# MKW36Z4 register map
Vendor: NXP Semiconductors; Series: Kinetis_W; File version: 1.6
CPU: CM0PLUS r0p0, little endian, no MPU, no FPU, VTOR, 2 interrupt priority bits
Registers are 16-bit, read-write, no defined reset value unless marked. A register's access mark holds for its fields unless they carry their own. Offsets are from the block's base; [hi:lo] are bit positions; {n}, {i} and the like mark numbered series; 'fields as' and 'values as' point back to an identical list.

## PORTC — PORT
Base 0x4004B000
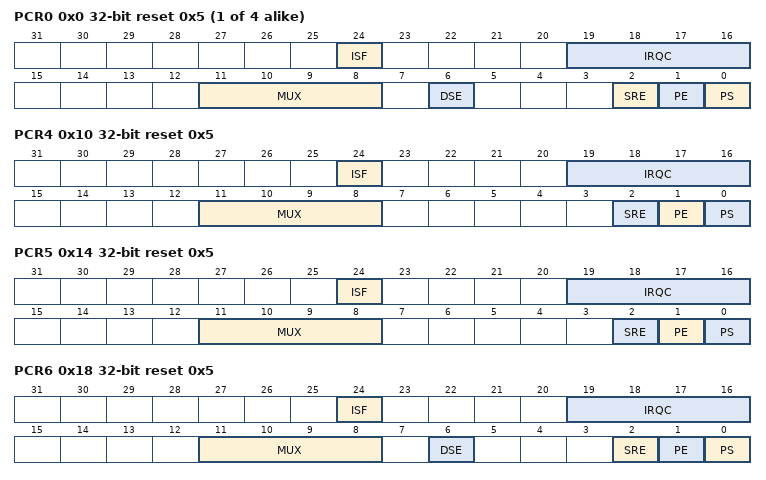
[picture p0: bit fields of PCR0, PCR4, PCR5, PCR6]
{0x0+4i} PCR{i} 32-bit reset 0x5 (i=0..3) — Pin Control Register {i}
  [24] ISF — Interrupt Status Flag
    0=Configured interrupt is not detected
  [19:16] IRQC — Interrupt Configuration
    0=Interrupt Status Flag (ISF) is disabled; 1=ISF flag and DMA request on rising edge; 2=ISF flag and DMA request on falling edge; 3=ISF flag and DMA request on either edge; 8=ISF flag and Interrupt when logic 0; 9=ISF flag and Interrupt on rising-edge; 10=ISF flag and Interrupt on falling-edge; 11=ISF flag and Interrupt on either edge; 12=ISF flag and Interrupt when logic 1
  [11:8] MUX — Pin Mux Control
    0=Pin disabled (Alternative 0) (analog); 1=Alternative 1 (GPIO); {v}=Alternative {v} (chip-specific) (v=2..15)
  [6] DSE — Drive Strength Enable
    0=Low drive strength is configured on the corresponding pin, if pin is configured as a digital output; 1=High drive strength is configured on the corresponding pin, if pin is configured as a digital output
  [2] SRE — Slew Rate Enable
    0=Fast slew rate is configured on the corresponding pin, if the pin is configured as a digital output; 1=Slow slew rate is configured on the corresponding pin, if the pin is configured as a digital output
  [1] PE — Pull Enable
  [0] PS — Pull Select
    0=Internal pulldown resistor is enabled on the corresponding pin, if the corresponding PE field is set; 1=Internal pullup resistor is enabled on the corresponding pin, if the corresponding PE field is set
0x10 PCR4 32-bit reset 0x5 — Pin Control Register 4
  [24] ISF — Interrupt Status Flag
    0=Configured interrupt is not detected
  [19:16] IRQC — Interrupt Configuration
    values as PCR0.IRQC
  [11:8] MUX — Pin Mux Control
    values as PCR0.MUX
  [2] SRE — Slew Rate Enable
    values as PCR0.SRE
  [1] PE — Pull Enable
  [0] PS — Pull Select
    values as PCR0.PS
0x14 PCR5 32-bit reset 0x5 — Pin Control Register 5
  fields as PCR4
0x18 PCR6 32-bit reset 0x5 — Pin Control Register 6
  fields as PCR0
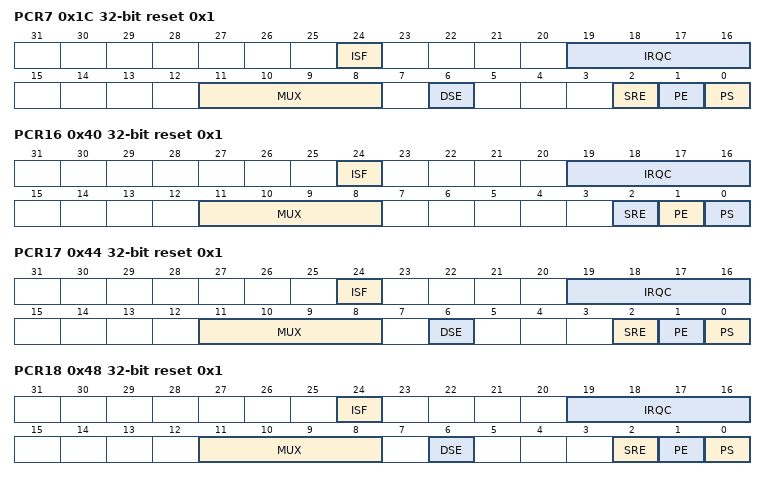
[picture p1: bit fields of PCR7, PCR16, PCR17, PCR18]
0x1C PCR7 32-bit reset 0x1 — Pin Control Register 7
  fields as PCR0
0x40 PCR16 32-bit reset 0x1 — Pin Control Register 16
  fields as PCR4
0x44 PCR17 32-bit reset 0x1 — Pin Control Register 17
  fields as PCR0
0x48 PCR18 32-bit reset 0x1 — Pin Control Register 18
  fields as PCR0
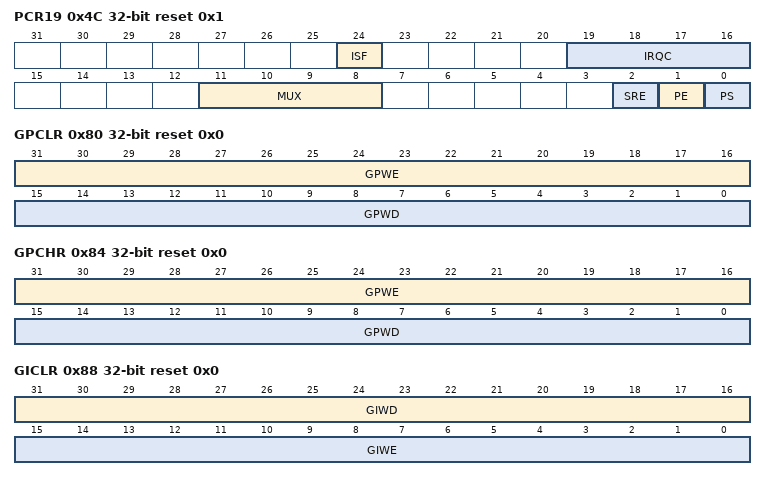
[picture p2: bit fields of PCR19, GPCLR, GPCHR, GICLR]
0x4C PCR19 32-bit reset 0x1 — Pin Control Register 19
  fields as PCR4
0x80 GPCLR 32-bit wo reset 0x0 — Global Pin Control Low Register
  [31:16] GPWE — Global Pin Write Enable
  [15:0] GPWD — Global Pin Write Data
0x84 GPCHR 32-bit wo reset 0x0 — Global Pin Control High Register
  fields as GPCLR
0x88 GICLR 32-bit wo reset 0x0 — Global Interrupt Control Low Register
  [31:16] GIWD — Global Interrupt Write Data
  [15:0] GIWE — Global Interrupt Write Enable
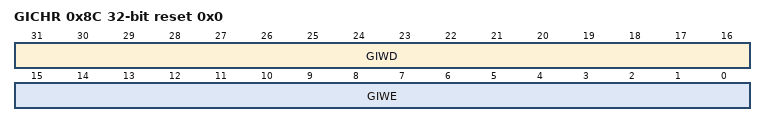
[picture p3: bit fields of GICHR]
0x8C GICHR 32-bit wo reset 0x0 — Global Interrupt Control High Register
  fields as GICLR
0xA0 ISFR 32-bit reset 0x0 — Interrupt Status Flag Register
  [31:0] ISF — Interrupt Status Flag

## BTLE_RF
Base 0x4005B000
0x600 BLE_PART_ID ro reset 0x5 — BLUETOOTH LOW ENERGY PART ID
  [15:0] BLE_PART_ID
    0=Pre-production; 1=Pre-production; 2=KW40; 3=KW41; 4=K3S; 5=KW35/KW36
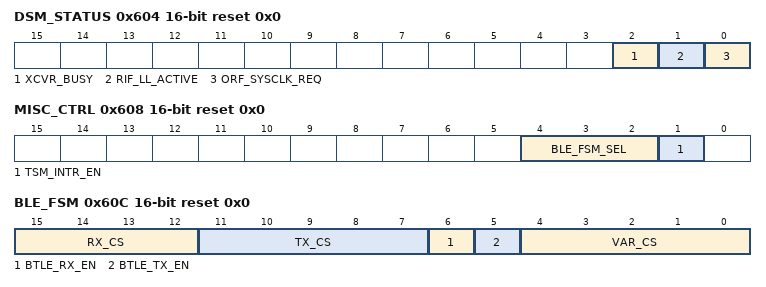
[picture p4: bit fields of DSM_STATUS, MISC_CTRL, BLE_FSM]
0x604 DSM_STATUS ro reset 0x0 (reset mask 0xFFF8) — BLE DSM STATUS
  [2] XCVR_BUSY — Transceiver Busy Status Bit
    0=RF Channel in available (TSM is idle); 1=RF Channel in use (TSM is busy)
  [1] RIF_LL_ACTIVE — Link Layer Active
  [0] ORF_SYSCLK_REQ — RF Oscillator Requested
0x608 MISC_CTRL reset 0x0 — BLE MISCELLANEOUS CONTROL
  [4:2] BLE_FSM_SEL — BLE FSM Selector
  [1] TSM_INTR_EN — TSM Interrupt Enable
0x60C BLE_FSM ro reset 0x0 — BLE STATE MACHINE STATUS
  [15:12] RX_CS — BLE RX State Machine Current State
  [11:7] TX_CS — BLE TX State Machine Current State
  [6] BTLE_RX_EN — BLE RX Enable Control to TSM
  [5] BTLE_TX_EN — BLE TX Enable Control to TSM
  [4:0] VAR_CS — Variable State Machine Current State
